# AT32F403A register map
Vendor: Keil; Series: AT32F403A; File version: 1.0
CPU: CM4 r0p1, little endian, no MPU, FPU, 4 interrupt priority bits
Registers are 32-bit, read-write, reset 0x0 unless marked. A register's access mark holds for its fields unless they carry their own. Offsets are from the block's base; [hi:lo] are bit positions; {n}, {i} and the like mark numbered series.

## CRC — CRC calculation unit
Base 0x40023000
0x00 DT reset 0xFFFFFFFF — Data register
0x04 CDT — Common data register
  [7:0] CDT — Common Data
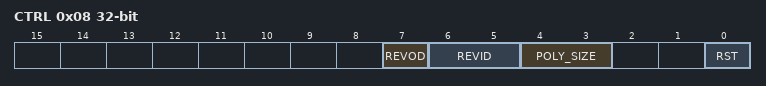
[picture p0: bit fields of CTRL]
0x08 CTRL — Control register
  [7] REVOD — Reverse output data
    0=NoEffect; 1=WordReverse
  [6:5] REVID — Reverse input data
    0=NoEffect; 1=ByteReverse; 2=HalfWordReverse; 3=WordReverse
  [4:3] POLY_SIZE — Polynomial size
    0=bits32 (32 bits); 1=bits16 (16 bits); 2=bits8 (8 bits); 3=bits7 (7 bits)
  [0] RST write-1-sets — Reset bit
    on write: 1=Reset CRC calculation unit, the data register is set as 0xFFFF FFFF
0x10 IDT reset 0xFFFFFFFF — Initial data register
0x14 POLY reset 0x4C11DB7 — Polynomial coefficient register

## NVIC — Nested Vectored Interrupt Controller
Base 0xE000E000
0x04 ICTR ro — Interrupt Controller Type Register
  [3:0] INTLINESNUM — Total number of interrupt lines in groups
0x100 ISER0 — Interrupt Set-Enable Register
  [31:0] SETENA
0x104 ISER1 — Interrupt Set-Enable Register
  [31:0] SETENA
0x180 ICER0 — Interrupt Clear-Enable Register
  [31:0] CLRENA
0x184 ICER1 — Interrupt Clear-Enable Register
  [31:0] CLRENA
0x200 ISPR0 — Interrupt Set-Pending Register
  [31:0] SETPEND
0x204 ISPR1 — Interrupt Set-Pending Register
  [31:0] SETPEND
0x280 ICPR0 — Interrupt Clear-Pending Register
  [31:0] CLRPEND
0x284 ICPR1 — Interrupt Clear-Pending Register
  [31:0] CLRPEND
0x300 IABR0 ro — Interrupt Active Bit Register
  [31:0] ACTIVE
0x304 IABR1 ro — Interrupt Active Bit Register
  [31:0] ACTIVE
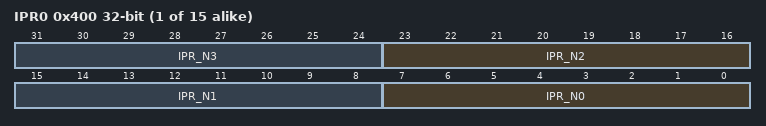
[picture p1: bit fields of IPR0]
{0x400+4i} IPR{i} (i=0..14) — Interrupt Priority Register
  [8n+7:8n] IPR_N{n} (n=0..3)
0xF00 STIR wo — Software Triggered Interrupt Register
  [8:0] INTID — interrupt to be triggered

## USBFS — Universal serial bus full-speed device interface
Base 0x40005C00
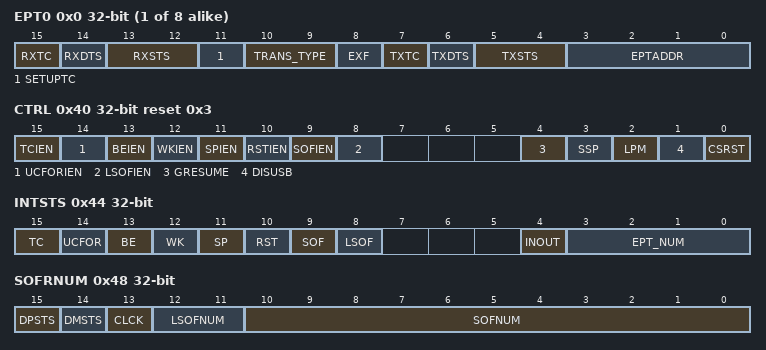
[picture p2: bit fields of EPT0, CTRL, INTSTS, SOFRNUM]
{0x0+4i} EPT{i} (i=0..7) — endpoint {i} register
  [15] RXTC — Rx transaction completed
  [14] RXDTS — Rx data toggle synchronization
  [13:12] RXSTS — Rx Status
  [11] SETUPTC — Setup transaction completed
  [10:9] TRANS_TYPE — Transfer type
  [8] EXF — Endpoint extend function
  [7] TXTC — Tx transaction completed
  [6] TXDTS — Tx data toggle synchronization
  [5:4] TXSTS — Tx status
  [3:0] EPTADDR — Endpoint address
0x40 CTRL reset 0x3 — control register
  [15] TCIEN — transmission completed interrupt enable
  [14] UCFORIEN — USB Core fifo overrun interrupt enable
  [13] BEIEN — Bus error interrupt enable
  [12] WKIEN — Wakeup/Remote wakeup interrupt enable
  [11] SPIEN — Bus suspend mode interrupt enable
  [10] RSTIEN — Bus reset interrupt enable
  [9] SOFIEN — Start of frame interrupt enable
  [8] LSOFIEN — Lost start of frame interrupt enable
  [4] GRESUME — Generate resume request
  [3] SSP — Soft suspend config
  [2] LPM — Low power mode
  [1] DISUSB — Disable usb phy
  [0] CSRST — Core soft reset
0x44 INTSTS — interrupt status register
  [15] TC — transaction completed
  [14] UCFOR — USB core fifo overrun memory
  [13] BE — Bus error
  [12] WK — Wakeup
  [11] SP — Bus suspend
  [10] RST — Bus reset
  [9] SOF — start of frame
  [8] LSOF — Lost start of frame
  [4] INOUT — In/Out transaction
  [3:0] EPT_NUM — Endpoint number
0x48 SOFRNUM — frame number register
  [15] DPSTS — DP status
  [14] DMSTS — DM status
  [13] CLCK — Connect locked
  [12:11] LSOFNUM — Lost start of frame number
  [10:0] SOFNUM — Start of frame number
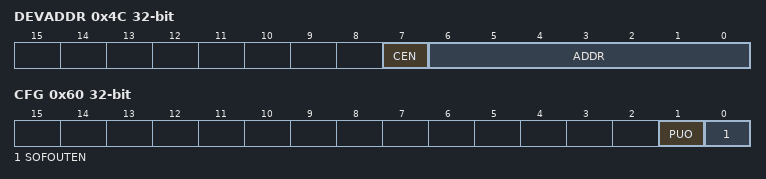
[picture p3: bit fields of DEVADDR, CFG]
0x4C DEVADDR — device address
  [7] CEN — USB core enable
  [6:0] ADDR — Host assign device address
0x50 BUFTBL — Buffer table address
  [15:3] BTADDR — Endpoint buffer table start address
0x60 CFG — CFG control register
  [1] PUO — DP pullup off
  [0] SOFOUTEN — SOF output enable
